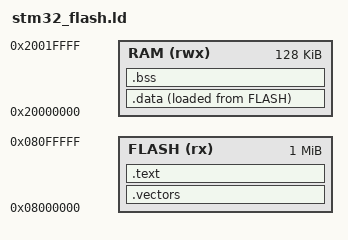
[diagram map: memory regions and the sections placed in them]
MEMORY
{
    FLASH (rx)  : ORIGIN = 0x08000000, LENGTH = 1024K
    RAM   (rwx) : ORIGIN = 0x20000000, LENGTH = 128K
}

_stack_size = 0x1000;

_stack_top = ORIGIN(RAM) + LENGTH(RAM);

ENTRY(reset_handler)

SECTIONS
{
    .vectors :
    {
        . = ALIGN(4);
        KEEP(*(.vectors))
        . = ALIGN(4);
    } > FLASH

    .text :
    {
        . = ALIGN(4);
        *(.text)
        *(.text*)
        *(.rodata)
        *(.rodata*)
        . = ALIGN(4);
        _text_end = .;
    } > FLASH

    .data :
    {
        . = ALIGN(4);
        _data_lma = LOADADDR(.data);
        _data_start = .;
        *(.data)
        *(.data*)
        . = ALIGN(4);
        _data_end = .;
    } > RAM AT> FLASH

    .bss :
    {
        . = ALIGN(4);
        _bss_start = .;
        *(.bss)
        *(.bss*)
        *(COMMON)
        . = ALIGN(4);
        _bss_end = .;
    } > RAM

    . = ALIGN(4);
    _heap_end = .;

    ASSERT(_bss_end + _stack_size <= ORIGIN(RAM) + LENGTH(RAM),
           "ERROR: RAM overflow! Giam stack_size hoac xoa bot bien")
}
